AUTOSAR XML (schema 4-2-2)
standard types defined: float32
package /DataTypes
  impl type float32_impl: category=VALUE, base-type=float32
  app type float32_AppView: category=VALUE
  application record data type Pose_T: category=STRUCTURE
    application record element x: category=VALUE, type=float32_AppView
  data type mapping set DataTypeMappingSet: data-type-map{application-data-type=float32_AppView, implementation-data-type=float32_impl}
package /PortInterfaces
  sender receiver interface IExample
    data value: type=Pose_T
package /ComponentTypes
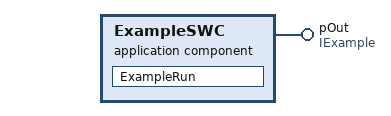
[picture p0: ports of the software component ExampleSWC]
  application sw component type ExampleSWC
    provide port pOut: provided-interface=IExample
    behavior ExampleSWC_InternalBehavior
      runnable ExampleRun
